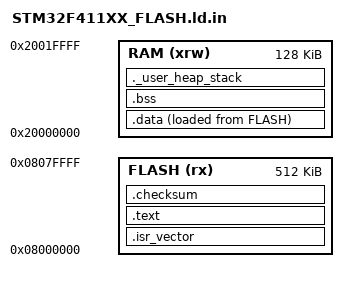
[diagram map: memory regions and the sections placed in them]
/* Synthetic configure-only template: substitution and section preservation. */
MEMORY
{
  FLASH (rx) : ORIGIN = 0x08000000, LENGTH = 512K
  RAM (xrw) : ORIGIN = 0x20000000, LENGTH = 128K
}
_estack = ORIGIN(RAM) + LENGTH(RAM);
_Min_Heap_Size = @HEAP_SIZE@;
_Min_Stack_Size = @STACK_SIZE@;
SECTIONS
{
  .isr_vector : { KEEP(*(.isr_vector)) } > FLASH
  .text @USE_READONLY@ : { *(.text*) *(.rodata*) } > FLASH
  .checksum : { KEEP(*(.checksum)) } > FLASH
  .data : { *(.data*) } > RAM AT > FLASH
  .bss : { *(.bss*) *(COMMON) } > RAM
  ._user_heap_stack (NOLOAD) :
  {
    . = ALIGN(8);
    . = . + _Min_Heap_Size;
    . = . + _Min_Stack_Size;
  } > RAM
}
